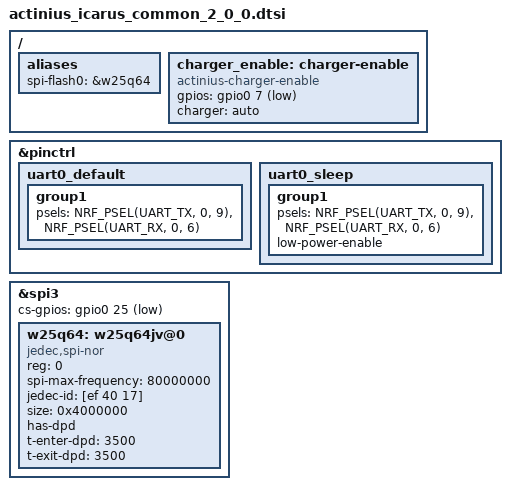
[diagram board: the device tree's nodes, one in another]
/*
 * Copyright (c) 2022 Actinius
 *
 * SPDX-License-Identifier: Apache-2.0
 */

&pinctrl {
	uart0_default: uart0_default {
		group1 {
			psels = <NRF_PSEL(UART_TX, 0, 9)>,
				<NRF_PSEL(UART_RX, 0, 6)>;
		};
	};

	uart0_sleep: uart0_sleep {
		group1 {
			psels = <NRF_PSEL(UART_TX, 0, 9)>,
				<NRF_PSEL(UART_RX, 0, 6)>;
			low-power-enable;
		};
	};
};

&spi3 {
	status = "okay";

	cs-gpios = <&gpio0 25 GPIO_ACTIVE_LOW>;

	w25q64: w25q64jv@0 {
		compatible = "jedec,spi-nor";
		reg = <0>;
		spi-max-frequency = <80000000>;
		jedec-id = [ef 40 17];
		size = <0x4000000>;
		has-dpd;
		t-enter-dpd = <3500>;
		t-exit-dpd = <3500>;
	};
};

/ {
	aliases {
		spi-flash0 = &w25q64;
	};

	charger_enable: charger-enable {
		compatible = "actinius-charger-enable";
		gpios = <&gpio0 7 GPIO_ACTIVE_LOW>;
		charger = "auto";
	};
};
